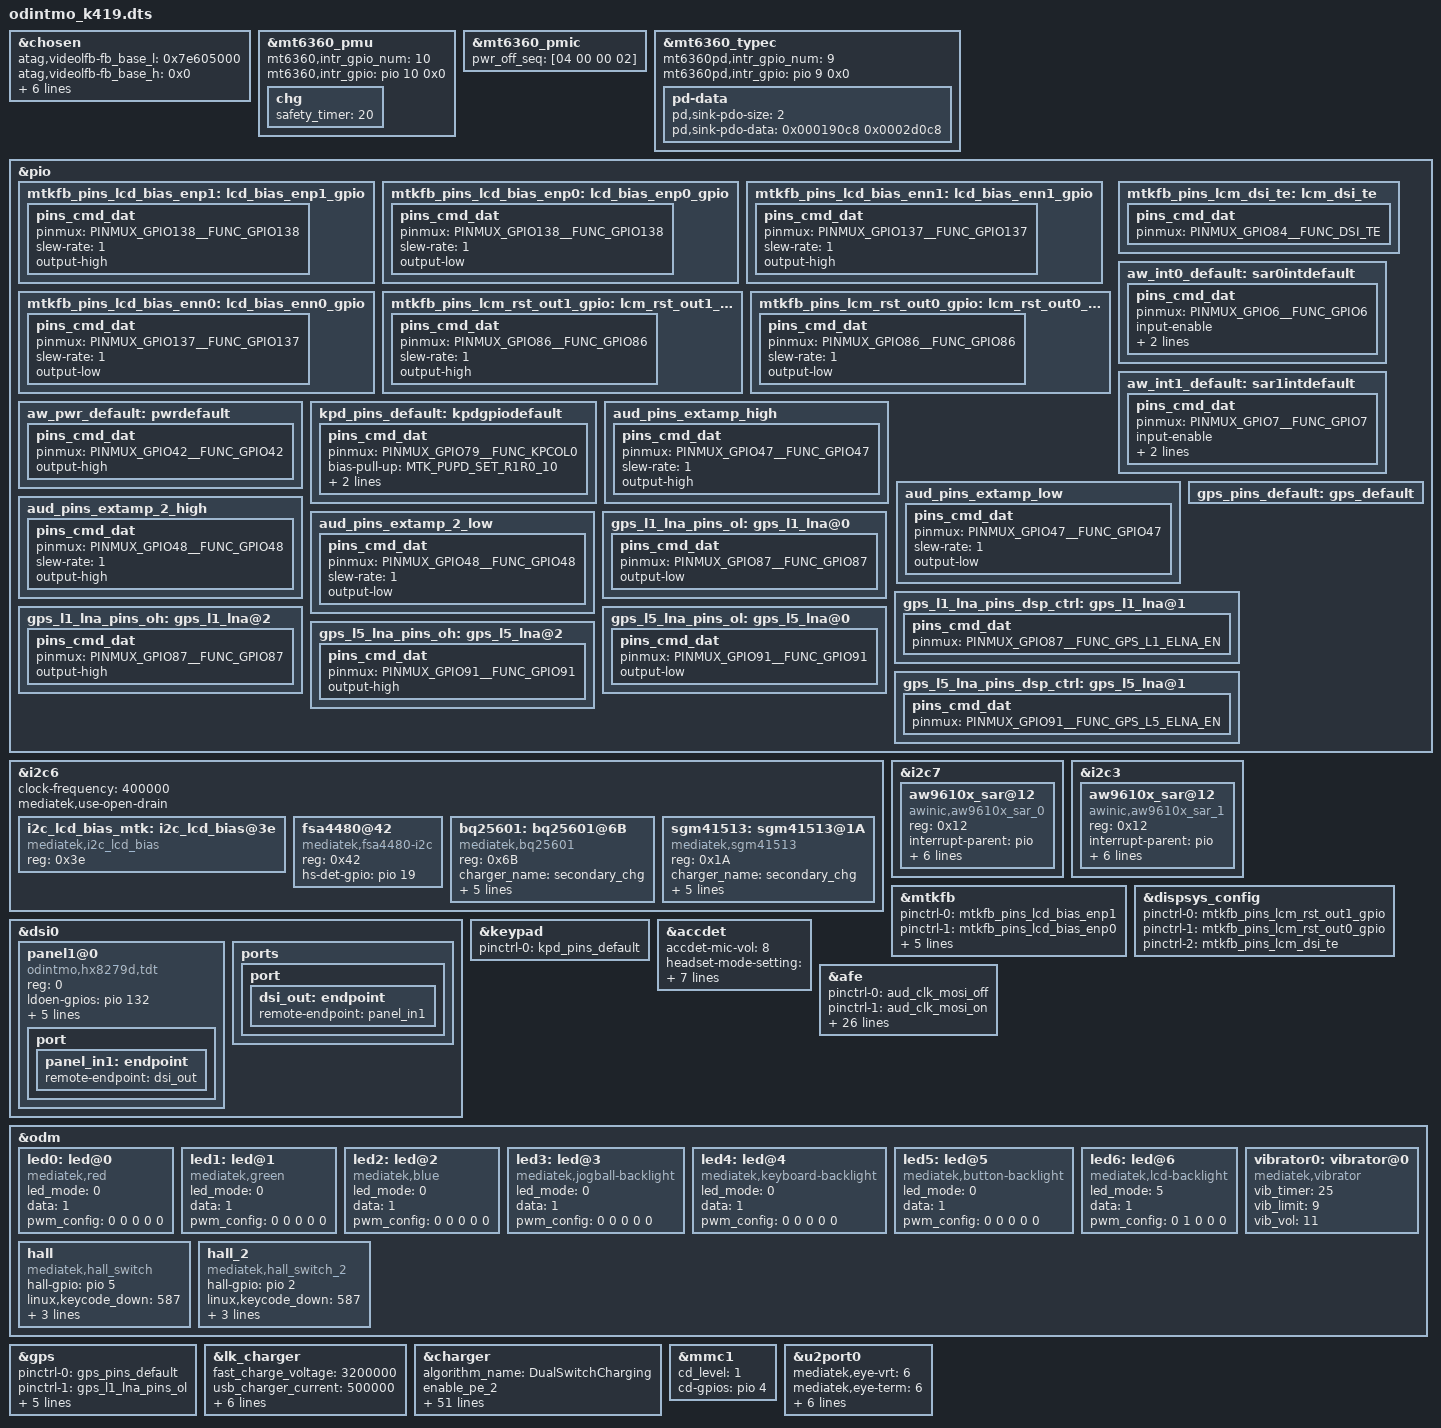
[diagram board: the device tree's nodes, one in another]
// SPDX-License-Identifier: GPL-2.0
/dts-v1/;
/plugin/;
#include <dt-bindings/interrupt-controller/irq.h>
#include <dt-bindings/interrupt-controller/arm-gic.h>
#ifndef CONFIG_FPGA_EARLY_PORTING
#include <dt-bindings/pinctrl/mt6833-pinfunc.h>
#endif

/* chosen */
&chosen {
	atag,videolfb-fb_base_l = <0x7e605000>;
	atag,videolfb-fb_base_h = <0x0>;
	atag,videolfb-islcmfound = <1>;
	atag,videolfb-islcm_inited = <0>;
	atag,videolfb-fps= <6000>;
	atag,videolfb-vramSize= <0x1be0000>;
	atag,videolfb-lcmname=
		"nt35595_fhd_dsi_cmd_truly_nt50358_drv";
};

&mt6360_pmu {
	mt6360,intr_gpio_num = <10>; /* direct defined GPIO num */
	mt6360,intr_gpio = <&pio 10 0x0>;
    /* Begin added by weijun for charging time on 2022-03-22 */
	chg {
		safety_timer = <20>;		/* hour */
	};
    /* End added by weijun for charging time on 2022-03-22 */
};

&mt6360_pmic {
	pwr_off_seq = [04 00 00 02];
};


&mt6360_typec {
/* Modify-start by baiwei.peng for type-c pd eint on 2022/03/15 */
	mt6360pd,intr_gpio_num = <9>; /* direct defined GPIO num */
	mt6360pd,intr_gpio = <&pio 9 0x0>;
/* Modify-end by baiwei.peng for type-c pd eint on 2022/03/15 */
/*Begin add for support 9V/2A with PD2.0 by wanglin.chen on 2021.11.16*/
	pd-data {
		pd,sink-pdo-size = <2>;
		/*(5V, 2A), (9V, 2A)*/
 		pd,sink-pdo-data = <0x000190c8 0x0002d0c8>;
	};
/*End add for support 9V/2A with PD2.0 by wanglin.chen on 2021.11.16*/
};

#ifndef CONFIG_FPGA_EARLY_PORTING
&pio {
	mtkfb_pins_lcd_bias_enp1: lcd_bias_enp1_gpio {
		pins_cmd_dat {
			pinmux = <PINMUX_GPIO138__FUNC_GPIO138>;
			slew-rate = <1>;
			output-high;
		};
	};

	mtkfb_pins_lcd_bias_enp0: lcd_bias_enp0_gpio {
		pins_cmd_dat {
			pinmux = <PINMUX_GPIO138__FUNC_GPIO138>;
			slew-rate = <1>;
			output-low;
		};
	};

	mtkfb_pins_lcd_bias_enn1: lcd_bias_enn1_gpio {
		pins_cmd_dat {
			pinmux = <PINMUX_GPIO137__FUNC_GPIO137>;
			slew-rate = <1>;
			output-high;
		};
	};

	mtkfb_pins_lcd_bias_enn0: lcd_bias_enn0_gpio {
		pins_cmd_dat {
			pinmux = <PINMUX_GPIO137__FUNC_GPIO137>;
			slew-rate = <1>;
			output-low;
		};
	};

	mtkfb_pins_lcm_rst_out1_gpio: lcm_rst_out1_gpio {
		pins_cmd_dat {
			pinmux = <PINMUX_GPIO86__FUNC_GPIO86>;
			slew-rate = <1>;
			output-high;
		};
	};

	mtkfb_pins_lcm_rst_out0_gpio: lcm_rst_out0_gpio {
		pins_cmd_dat {
			pinmux = <PINMUX_GPIO86__FUNC_GPIO86>;
			slew-rate = <1>;
			output-low;
		};
	};
	mtkfb_pins_lcm_dsi_te: lcm_dsi_te {
		pins_cmd_dat {
			pinmux = <PINMUX_GPIO84__FUNC_DSI_TE>;
		};
	};
};


/* LCD Bias I2C */
&i2c6 {
	#address-cells = <1>;
	#size-cells = <0>;
	clock-frequency = <400000>;
	mediatek,use-open-drain;
	i2c_lcd_bias_mtk:i2c_lcd_bias@3e {
		compatible = "mediatek,i2c_lcd_bias";
		reg = <0x3e>;
		status = "okay";
	 };
};

/* Add-start by baiwei.peng for sar sensor porting on 2022/03/16 */
&pio {
	aw_int0_default: sar0intdefault {
		pins_cmd_dat {
			pinmux = <PINMUX_GPIO6__FUNC_GPIO6>;
			input-enable;
			bias-pull-up;
			drive-strength = <7>;
		};
	};
	aw_int1_default: sar1intdefault {
		pins_cmd_dat {
			pinmux = <PINMUX_GPIO7__FUNC_GPIO7>;
			input-enable;
			bias-pull-up;
			drive-strength = <7>;
		};

	};
	aw_pwr_default: pwrdefault {
		pins_cmd_dat {
			pinmux = <PINMUX_GPIO42__FUNC_GPIO42>;
			output-high;
		};
	};
};

&i2c7 {
	status = "okay";
	aw9610x_sar@12 {
		compatible = "awinic,aw9610x_sar_0";
		reg = <0x12>;
		interrupt-parent = <&pio>;
		interrupts = <6 IRQ_TYPE_EDGE_FALLING 6 0>;
		irq-gpio = <&pio 6 0>;
		aw9610x,using-firmware;
		sar-num = < 0 >;
		pinctrl-names = "default";
		pinctrl-0 = <&aw_int0_default>;
		channel-func = <0x03>;
		status = "okay";
	};
};

&i2c3 {
	status = "okay";
	aw9610x_sar@12 {
		compatible = "awinic,aw9610x_sar_1";
		reg = <0x12>;
		interrupt-parent = <&pio>;
		interrupts = <7 IRQ_TYPE_EDGE_FALLING 7 0>;
		irq-gpio = <&pio 7 0>;
		pinctrl-names = "default";
		pinctrl-0 = <&aw_int1_default &aw_pwr_default>;
		aw9610x,using-firmware;
		sar-num = < 1 >;
		channel-func = <0x03>;
		status = "okay";
	};
};
/* Add-end by baiwei.peng for sar sensor porting on 2022/03/16 */

/* for reset && +-5.5V pin control */
&mtkfb {
	pinctrl-names = "lcd_bias_enp1_gpio", "lcd_bias_enp0_gpio",
		"lcd_bias_enn1_gpio", "lcd_bias_enn0_gpio",
		"lcm_rst_out1_gpio", "lcm_rst_out0_gpio",
		"mode_te_te";
	pinctrl-0 = <&mtkfb_pins_lcd_bias_enp1>;
	pinctrl-1 = <&mtkfb_pins_lcd_bias_enp0>;
	pinctrl-2 = <&mtkfb_pins_lcd_bias_enn1>;
	pinctrl-3 = <&mtkfb_pins_lcd_bias_enn0>;
	pinctrl-4 = <&mtkfb_pins_lcm_rst_out1_gpio>;
	pinctrl-5 = <&mtkfb_pins_lcm_rst_out0_gpio>;
	pinctrl-6 = <&mtkfb_pins_lcm_dsi_te>;
	status = "okay";
};
&dispsys_config {
	pinctrl-names =
		"lcm_rst_out1_gpio", "lcm_rst_out0_gpio",
		"mode_te_te";
	pinctrl-0 = <&mtkfb_pins_lcm_rst_out1_gpio>;
	pinctrl-1 = <&mtkfb_pins_lcm_rst_out0_gpio>;
	pinctrl-2 = <&mtkfb_pins_lcm_dsi_te>;
	status = "okay";
};

&dsi0 {
	status = "okay";
	#address-cells = <1>;
	#size-cells = <0>;
	//fake_heigh = <1920>;
	//fake_width = <1080>;
	panel1@0 {
	//	compatible = "challenger,sw49110,csot";
	    compatible = "odintmo,hx8279d,tdt";
    	reg = <0>;
		//pm-enable-gpios = <&pio 136 0>; /* PERIEN_LCM_LED_EN */
        ldoen-gpios = <&pio 132 0>; //lcd 3.3V
		ldo1v8-gpios = <&pio 136 0>;
                reset-gpios = <&pio 86 0>; /* LCM reset */
        id0-gpios = <&pio 22 0>;
        id1-gpios = <&pio 21 0>;
		bias-gpios = <&pio 137 0>, <&pio 138 0>; /* +-5.5V */
		pinctrl-names = "default";
		port {
			panel_in1: endpoint {
				remote-endpoint = <&dsi_out>;
			};
		};
	};
	/*panel3@0 {
		compatible = "truly,ft8756,vdo";
		reg = <2>;
		pm-enable-gpios = <&pio 136 0>;
		reset-gpios = <&pio 86 0>;
		bias-gpios = <&pio 137 0>,
			<&pio 138 0>;
		pinctrl-names = "default";
		port {
			panel_in3: endpoint {
				remote-endpoint = <&dsi_out>;
			};
		};
	}; */
	ports {
		port {
			dsi_out: endpoint {
				remote-endpoint = <&panel_in1>;
			};
		};
	};
};
#endif

&keypad {
	pinctrl-names = "default";
	pinctrl-0 = <&kpd_pins_default>;
};

&pio {
	kpd_pins_default: kpdgpiodefault {
		pins_cmd_dat {
			pinmux = <PINMUX_GPIO79__FUNC_KPCOL0>;
			bias-pull-up = <MTK_PUPD_SET_R1R0_10>;
			output-low;
			input-schmitt-enable;
		};
	};
};

/* Begin added by lanying.he for XR porting on 2022/01/05*/
&i2c6 {
	fsa4480@42 {
		compatible = "mediatek,fsa4480-i2c";
		reg = <0x42>;
		hs-det-gpio = <&pio 19 0x0>;
		status = "okay";
	};
};

/* End added by lanying.he for XR porting on 2022/01/05*/

/* accdet start */
&accdet {
	/* accdet micbias voltage: 0x09:2.85v 0x08:2.8v 0x07,
	 * 2.7v;0x05,2.5v;0x02,1.9v
	 */
	accdet-mic-vol = <8>;
	/* accdet pwm_width, pwm_thresh, fall_delay, rise_delay
	 * debounce0, debounce1, debounce3, debounce4
	 * eint pwm_width, eint pwm_thresh
	 * eint deb(debounce0, debounce1, debounce2, debounce3), inv_debounce
	 */
	headset-mode-setting = <0x500 0x500 1 0x1f0
				0x800 0x800 0x20 0x44
				0x4 0x1
				0x5 0x3 0x3 0x5 0xe>;
	accdet-plugout-debounce = <1>;
	/*1:ACC mode, 2:low cost without in bias, 6:low cost with in bias*/
	accdet-mic-mode = <2>;
	/*0--MD_MAX--UP_MAX--DW_MAX*/
	headset-three-key-threshold = <0 80 220 400>;
	headset-three-key-threshold-CDD = <0 121 192 600>;
	/*0--MD_MAX--VOICE_MAX--UP_MAX--DW_MAX*/
	headset-four-key-threshold = <0 58 121 192 400>;

	/* select VTH to 2v and 500k, use internal resitance */
	eint_use_ext_res = <0>;
	status = "okay";
};
/* accdet end */


&afe {
    pinctrl-names = "aud_clk_mosi_off",
				"aud_clk_mosi_on",
				"aud_dat_mosi_off",
				"aud_dat_mosi_on",
				"aud_dat_miso0_off",
				"aud_dat_miso0_on",
				"aud_dat_miso1_off",
				"aud_dat_miso1_on",
				"vow_dat_miso_off",
				"vow_dat_miso_on",
				"vow_clk_miso_off",
				"vow_clk_miso_on",
				"aud_nle_mosi_off",
				"aud_nle_mosi_on",
				"aud_gpio_i2s0_off",
				"aud_gpio_i2s0_on",
				"aud_gpio_i2s1_off",
				"aud_gpio_i2s1_on",
				"aud_gpio_i2s2_off",
				"aud_gpio_i2s2_on",
				"aud_gpio_i2s3_off",
				"aud_gpio_i2s3_on",
				"aud_gpio_i2s5_off",
				"aud_gpio_i2s5_on",
				"extamp-pullhigh",
				"extamp-pulllow",
				"extamp2-pullhigh",
				"extamp2-pulllow";

		pinctrl-0 = <&aud_clk_mosi_off>;
		pinctrl-1 = <&aud_clk_mosi_on>;
		pinctrl-2 = <&aud_dat_mosi_off>;
		pinctrl-3 = <&aud_dat_mosi_on>;
		pinctrl-4 = <&aud_dat_miso0_off>;
		pinctrl-5 = <&aud_dat_miso0_on>;
		pinctrl-6 = <&aud_dat_miso1_off>;
		pinctrl-7 = <&aud_dat_miso1_on>;
		pinctrl-8 = <&vow_dat_miso_off>;
		pinctrl-9 = <&vow_dat_miso_on>;
		pinctrl-10 = <&vow_clk_miso_off>;
		pinctrl-11 = <&vow_clk_miso_on>;
		pinctrl-12 = <&aud_nle_mosi_off>;
		pinctrl-13 = <&aud_nle_mosi_on>;
		pinctrl-14 = <&aud_gpio_i2s0_off>;
		pinctrl-15 = <&aud_gpio_i2s0_on>;
		pinctrl-16 = <&aud_gpio_i2s1_off>;
		pinctrl-17 = <&aud_gpio_i2s1_on>;
		pinctrl-18 = <&aud_gpio_i2s2_off>;
		pinctrl-19 = <&aud_gpio_i2s2_on>;
		pinctrl-20 = <&aud_gpio_i2s3_off>;
		pinctrl-21 = <&aud_gpio_i2s3_on>;
		pinctrl-22 = <&aud_gpio_i2s5_off>;
		pinctrl-23 = <&aud_gpio_i2s5_on>;
		pinctrl-24 = <&aud_pins_extamp_high>;
       		pinctrl-25 = <&aud_pins_extamp_low>;
		pinctrl-26 = <&aud_pins_extamp_2_high>;
        	pinctrl-27 = <&aud_pins_extamp_2_low>;
};
&pio {
	aud_pins_extamp_high: aud_pins_extamp_high {
		pins_cmd_dat {
			pinmux = <PINMUX_GPIO47__FUNC_GPIO47>;
			slew-rate = <1>;
			output-high;
		};
	};
	aud_pins_extamp_low: aud_pins_extamp_low {
		pins_cmd_dat {
			pinmux = <PINMUX_GPIO47__FUNC_GPIO47>;
			slew-rate = <1>;
			output-low;
		};
	};
aud_pins_extamp_2_high: aud_pins_extamp_2_high {
		pins_cmd_dat {
			pinmux = <PINMUX_GPIO48__FUNC_GPIO48>;
			slew-rate = <1>;
			output-high;
		};
	};
	aud_pins_extamp_2_low: aud_pins_extamp_2_low {
		pins_cmd_dat {
			pinmux = <PINMUX_GPIO48__FUNC_GPIO48>;
			slew-rate = <1>;
			output-low;
		};
	};
};

//End added by lanying.he for XR11082897 on 2021/05/06

&odm {
	led0:led@0 {
		compatible = "mediatek,red";
		led_mode = <0>;
		data = <1>;
		pwm_config = <0 0 0 0 0>;
	};
	led1:led@1 {
		compatible = "mediatek,green";
		led_mode = <0>;
		data = <1>;
		pwm_config = <0 0 0 0 0>;
	};
	led2:led@2 {
		compatible = "mediatek,blue";
		led_mode = <0>;
		data = <1>;
		pwm_config = <0 0 0 0 0>;
	};
	led3:led@3 {
		compatible = "mediatek,jogball-backlight";
		led_mode = <0>;
		data = <1>;
		pwm_config = <0 0 0 0 0>;
	};
	led4:led@4 {
		compatible = "mediatek,keyboard-backlight";
		led_mode = <0>;
		data = <1>;
		pwm_config = <0 0 0 0 0>;
	};
	led5:led@5 {
		compatible = "mediatek,button-backlight";
		led_mode = <0>;
		data = <1>;
		pwm_config = <0 0 0 0 0>;
	};
	led6:led@6 {
		compatible = "mediatek,lcd-backlight";
		led_mode = <5>;
		data = <1>;
		pwm_config = <0 1 0 0 0>;
	};
	vibrator0:vibrator@0 {
		compatible = "mediatek,vibrator";
		vib_timer = <25>;
		vib_limit = <9>;
		vib_vol= <11>; //Modified by baiwei.peng for vibrator effect
	};

/* Add-start by baiwei.peng for hall switch porting on 2022/03/16 */
	hall:hall {
		compatible = "mediatek,hall_switch";
		hall-gpio = <&pio 5 0x0>;
		linux,keycode_down = <587>;
		linux,keycode_up = <586>;
		interrupt-parent = <&pio>;
		interrupts = <5 IRQ_TYPE_LEVEL_LOW 5 0>;
	};

	hall_2:hall_2 {
		compatible = "mediatek,hall_switch_2";
		hall-gpio = <&pio 2 0x0>;
		linux,keycode_down = <587>;
		linux,keycode_up = <586>;
		interrupt-parent = <&pio>;
		interrupts = <2 IRQ_TYPE_LEVEL_LOW 2 0>;
	};
/* Add-end by baiwei.peng for sar sensor porting on 2022/03/16 */
};
/* GPS GPIO standardization start */
&pio {
	gps_pins_default: gps_default {
	};

	gps_l1_lna_pins_ol: gps_l1_lna@0 {
		pins_cmd_dat {
			pinmux = <PINMUX_GPIO87__FUNC_GPIO87>;
			output-low;
		};
	};
	gps_l1_lna_pins_dsp_ctrl: gps_l1_lna@1 {
		pins_cmd_dat {
			pinmux = <PINMUX_GPIO87__FUNC_GPS_L1_ELNA_EN>;
		};
	};
	gps_l1_lna_pins_oh: gps_l1_lna@2 {
		pins_cmd_dat {
			pinmux = <PINMUX_GPIO87__FUNC_GPIO87>;
			output-high;
		};
	};

	gps_l5_lna_pins_ol: gps_l5_lna@0 {
		pins_cmd_dat {
			pinmux = <PINMUX_GPIO91__FUNC_GPIO91>;
			output-low;
		};
	};
	gps_l5_lna_pins_dsp_ctrl: gps_l5_lna@1 {
		pins_cmd_dat {
			pinmux = <PINMUX_GPIO91__FUNC_GPS_L5_ELNA_EN>;
		};
	};
	gps_l5_lna_pins_oh: gps_l5_lna@2 {
		pins_cmd_dat {
			pinmux = <PINMUX_GPIO91__FUNC_GPIO91>;
			output-high;
		};
	};
};

&gps {
	pinctrl-names = "default",
		"gps_l1_lna_disable",
		"gps_l1_lna_dsp_ctrl",
		"gps_l1_lna_enable",
		"gps_l5_lna_disable",
		"gps_l5_lna_dsp_ctrl",
		"gps_l5_lna_enable";
	pinctrl-0 = <&gps_pins_default>;
	pinctrl-1 = <&gps_l1_lna_pins_ol>;
	pinctrl-2 = <&gps_l1_lna_pins_dsp_ctrl>;
	pinctrl-3 = <&gps_l1_lna_pins_oh>;
	pinctrl-4 = <&gps_l5_lna_pins_ol>;
	pinctrl-5 = <&gps_l5_lna_pins_dsp_ctrl>;
	pinctrl-6 = <&gps_l5_lna_pins_oh>;
	status = "okay";
};
/* GPS GPIO standardization end */

//Begin Modified by qiuguangliang for 10985708 on 2021-05-11
&lk_charger {
		fast_charge_voltage = <3200000>;

		/* charging current */
		usb_charger_current = <500000>;
		ac_charger_current = <1500000>;
		ac_charger_input_current = <1500000>;
		non_std_ac_charger_current = <500000>;
		charging_host_charger_current = <500000>;
		ta_ac_charger_current = <500000>;
		pd_charger_current = <500000>;

	};
&charger {
	algorithm_name = "DualSwitchCharging";
	enable_pe_2;
	ac_charger_current = <2050000>;
	ac_charger_input_current = <2050000>;
	ta_ac_charger_current = <4000000>;
	chg1_ta_ac_charger_current = <2000000>;
	chg2_ta_ac_charger_current = <2000000>;
	battery_cv = <4400000>;
	max_dmivr_charger_current = <2100000>;    //modified by dapeng.qiao for task 11242994 on 2021-06-11
	/* sw jeita */
	enable_sw_jeita;
    jeita_temp_above_t4_cv = <4100000>;
    jeita_temp_t3_to_t4_cv = <4100000>;
    jeita_temp_t2_to_t3_cv = <4400000>;
    jeita_temp_t1_to_t2_cv = <4400000>;
    jeita_temp_t0_to_t1_cv = <4400000>;
    jeita_temp_below_t0_cv = <4400000>;
//Begin modify by qiuguangliang for 11260953 on 20210623
    temp_t4_thres = <550>;
    temp_t4_thres_minus_x_degree = <510>;
    temp_t3_thres = <430>;
    temp_t3_thres_minus_x_degree = <400>;
    temp_t2_thres = <110>;
    temp_t2_thres_plus_x_degree = <100>;
    temp_t1_thres = <60>;
    temp_t1_thres_plus_x_degree = <50>;
    temp_t0_thres = <0>;
    temp_t0_thres_plus_x_degree = <10>;
    temp_neg_10_thres = <0>;
    min_charge_temp = <0>;
    min_charge_temp_plus_x_degree = <60>;
    max_charge_temp = <550>; //modified by qiuguangliang for task 11339205 on 2020-06-15
    max_charge_temp_minus_x_degree = <510>; //modified by qiuguangliang for task 11339205 on 2020-07-15
//End modify by qiuguangliang for 11260953 on 20210623
    jeita_temp_above_t4_current = <0>;
    jeita_temp_t3_to_t4_current = <2000000>;//modified by hailong.chen for task 9519701 on 2020-06-16
    jeita_temp_t2_to_t3_current = <4000000>;
    jeita_temp_t1_to_t2_current = <1200000>;
    jeita_temp_t0_to_t1_current = <1200000>;
    jeita_temp_below_t0_current = <0>;

    enable_step_chg;
    step_chg_vbat = <4290000>;
    step_chg_vbat_hysteresis = <70000>;
    step_chg_current = <3000000>;
    max_charger_voltage = <10500000>;
    ovp_restore_voltage = <9500000>;
	min_charger_voltage = <4400000>;
	min_charger_voltage_1 = <4400000>;
	min_charger_voltage_2 = <4400000>;
	max_charging_time = <72000>;//modified by qiuguangliang for task 11297685 on 2020-07-08

	/*PD2.0*/
	parallel_vbus;
	pd_vbus_low_bound = <5000000>;
	pd_vbus_upper_bound = <10000000>;
	pd_stop_battery_soc = <80>;
	ibus_err = <14>;
 	vsys_watt = <5000000>;

	};

 &i2c6 {
     #address-cells = <1>;
     #size-cells = <0>;
     clock-frequency = <400000>;
 
     bq25601:bq25601@6B {
         compatible = "mediatek,bq25601";
         reg = <0x6B>;
         status = "okay";
         charger_name = "secondary_chg";
         alias_name = "bq25601";
         gpio_bq25601_en_num = <131>;
         gpio_bq25601_en = <&pio 131 0x0>;
         gpio_bq25601_intr_num = <11>; /* direct defined GPIO num */
         gpio_bq25601_intr = <&pio 11 0x0>;
     };
 
      sgm41513:sgm41513@1A {
         compatible = "mediatek,sgm41513";
         reg = <0x1A>;
         status = "okay";
         charger_name = "secondary_chg";
         alias_name = "bq25601";
         gpio_bq25601_en_num = <131>;
         gpio_bq25601_en = <&pio 131 0x0>;
         gpio_bq25601_intr_num = <11>; /* direct defined GPIO num */
         gpio_bq25601_intr = <&pio 11 0x0>;
     }; 
 };

/*Add-start by baiwei.peng for sdcard porting on 2022/03/14 */
&mmc1 {
	cd_level = /bits/ 8 <1>;
	cd-gpios = <&pio 4 0>;
};
/*Add-end by baiwei.peng for sdcard porting on 2022/03/14 */

/* Add-start by baiwei.peng for usb eye diagram on 20220321 */
&u2port0 {
        mediatek,eye-vrt = <6>;
        mediatek,eye-term = <6>;
        mediatek,eye-rev6 = <3>;
        mediatek,eye-disc = <0>;
        mediatek,host-eye-vrt = <3>; /* 0~7 */
        mediatek,host-eye-term = <3>; /* 0~7 */
        mediatek,host-eye-rev6 = <1>; /* 0~3 */
        mediatek,host-eye-disc = <0>; /* 0~15 */
};
/* Add-end by baiwei.peng for usb eye diagram on 20220321 */

#include "mediatek/cust_mt6833_odintmo_camera.dtsi"
#include <odintmo_k419/cust.dtsi>
#include "mediatek/cust_mt6833_touch_odintmo_k419.dtsi"
//#include "mediatek/cust_mt6833_touch_1080x2300.dtsi"

#include "mediatek/bat_setting/odintmo/battery_prop_ext.dtsi"

/*End of this file, DO NOT ADD ANYTHING HERE*/
